# MAX32600 register map
File version: 1.0
Registers are 32-bit, read-write, reset 0x0 unless marked. A register's access mark holds for its fields unless they carry their own. Offsets are from the block's base; [hi:lo] are bit positions; {n}, {i} and the like mark numbered series.

## AFE — Analog Front End Controls
Base 0x4005401C
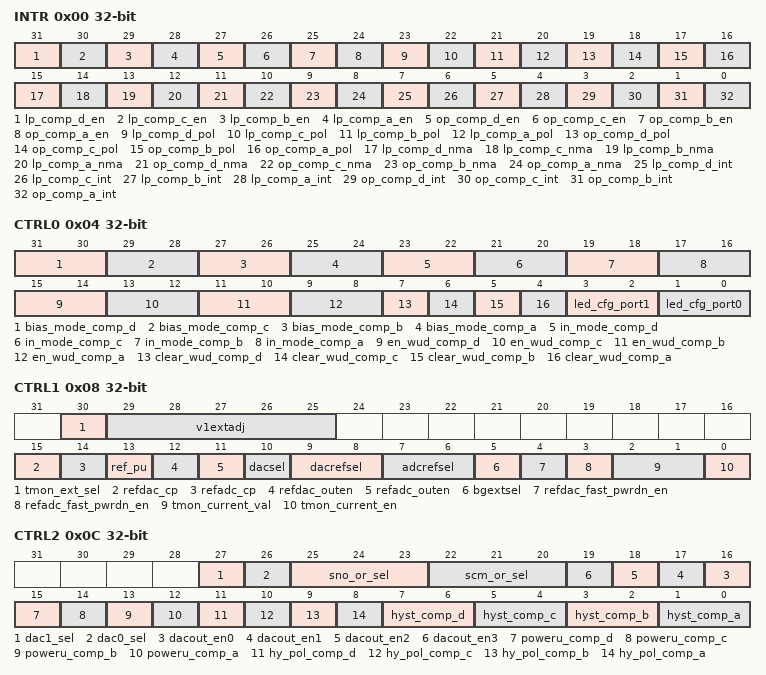
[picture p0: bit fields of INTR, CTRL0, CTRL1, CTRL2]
0x00 INTR — Analog Front End Interrupt Flags and Enable/Disable
  [31] lp_comp_d_en — Low-Power Comparator D Interrupt Enable/Disable
  [30] lp_comp_c_en — Low-Power Comparator C Interrupt Enable/Disable
  [29] lp_comp_b_en — Low-Power Comparator B Interrupt Enable/Disable
  [28] lp_comp_a_en — Low-Power Comparator A Interrupt Enable/Disable
  [27] op_comp_d_en — Op Amp Comparator D Interrupt Enable/Disable
  [26] op_comp_c_en — Op Amp Comparator C Interrupt Enable/Disable
  [25] op_comp_b_en — Op Amp Comparator B Interrupt Enable/Disable
  [24] op_comp_a_en — Op Amp Comparator A Interrupt Enable/Disable
  [23] lp_comp_d_pol — Low-Power Comparator D Polarity Select
  [22] lp_comp_c_pol — Low-Power Comparator C Polarity Select
  [21] lp_comp_b_pol — Low-Power Comparator B Polarity Select
  [20] lp_comp_a_pol — Low-Power Comparator A Polarity Select
  [19] op_comp_d_pol — Op Amp Comparator D Polarity Select
  [18] op_comp_c_pol — Op Amp Comparator C Polarity Select
  [17] op_comp_b_pol — Op Amp Comparator B Polarity Select
  [16] op_comp_a_pol — Op Amp Comparator A Polarity Select
  [15] lp_comp_d_nma write-1-clears — Low-Power Comparator D Non-Maskable Event Flag
  [14] lp_comp_c_nma write-1-clears — Low-Power Comparator C Non-Maskable Event Flag
  [13] lp_comp_b_nma write-1-clears — Low-Power Comparator B Non-Maskable Event Flag
  [12] lp_comp_a_nma write-1-clears — Low-Power Comparator A Non-Maskable Event Flag
  [11] op_comp_d_nma write-1-clears — Op Amp Comparator D Non-Maskable Event Flag
  [10] op_comp_c_nma write-1-clears — Op Amp Comparator C Non-Maskable Event Flag
  [9] op_comp_b_nma write-1-clears — Op Amp Comparator B Non-Maskable Event Flag
  [8] op_comp_a_nma write-1-clears — Op Amp Comparator A Non-Maskable Event Flag
  [7] lp_comp_d_int write-1-clears — Low-Power Comparator D Event Interrupt Flag
  [6] lp_comp_c_int write-1-clears — Low-Power Comparator C Event Interrupt Flag
  [5] lp_comp_b_int write-1-clears — Low-Power Comparator B Event Interrupt Flag
  [4] lp_comp_a_int write-1-clears — Low-Power Comparator A Event Interrupt Flag
  [3] op_comp_d_int write-1-clears — Op Amp D Comparator Event Interrupt Flag
  [2] op_comp_c_int write-1-clears — Op Amp C Comparator Event Interrupt Flag
  [1] op_comp_b_int write-1-clears — Op Amp B Comparator Event Interrupt Flag
  [0] op_comp_a_int write-1-clears — Op Amp A Comparator Event Interrupt Flag
0x04 CTRL0 — Analog Front End Control 0
  [31:30] bias_mode_comp_d — Low-Power Comparator D Bias Mode
  [29:28] bias_mode_comp_c — Low-Power Comparator C Bias Mode
  [27:26] bias_mode_comp_b — Low-Power Comparator B Bias Mode
  [25:24] bias_mode_comp_a — Low-Power Comparator A Bias Mode
  [23:22] in_mode_comp_d — Low-Power Comparator D Input Mode
  [21:20] in_mode_comp_c — Low-Power Comparator C Input Mode
  [19:18] in_mode_comp_b — Low-Power Comparator A Input Mode
  [17:16] in_mode_comp_a — Low-Power Comparator A Input Mode
  [15:14] en_wud_comp_d — Set Wakeup Detect for Low-Power Comparator D
  [13:12] en_wud_comp_c — Set Wakeup Detect for Low-Power Comparator C
  [11:10] en_wud_comp_b — Set Wakeup Detect for Low-Power Comparator B
  [9:8] en_wud_comp_a — Set Wakeup Detect for Low-Power Comparator A
  [7] clear_wud_comp_d — Clear Wakeup Detect for Low-Power Comparator D
  [6] clear_wud_comp_c — Clear Wakeup Detect for Low-Power Comparator C
  [5] clear_wud_comp_b — Clear Wakeup Detect for Low-Power Comparator B
  [4] clear_wud_comp_a — Clear Wakeup Detect for Low-Power Comparator A
  [3:2] led_cfg_port1 — LED Port 1 Drive Configuration
  [1:0] led_cfg_port0 — LED Port 0 Drive Configuration
0x08 CTRL1 — Analog Front End Control 1
  [30] tmon_ext_sel — Temperature Sense Current Source Routing Select
  [29:25] v1extadj
  [15] refdac_cp — DAC Reference Compensation Enable
  [14] refadc_cp — ADC Reference Compensation Enable
  [13] ref_pu — Reference Block Powerup
  [12] refdac_outen — DAC Reference Powerup
  [11] refadc_outen — Internal ADC Reference Output Enable
  [10] dacsel — DAC Reference Select
  [9:8] dacrefsel — DAC Reference Voltage Select
  [7:6] adcrefsel — ADC Reference Voltage Select
  [5] bgextsel — ADC/DAC Reference Select
  [4] refdac_fast_pwrdn_en — DAC Reference Fast Powerdown Enable
  [3] refadc_fast_pwrdn_en — ADC Reference Fast Powerdown Enable
  [2:1] tmon_current_val — Temperature Sense Current Source Value
  [0] tmon_current_en — Temperature Sense Current Source Enable
0x0C CTRL2 — Analog Front End Control 2
  [27] dac1_sel — Internal input stage select for dac1
  [26] dac0_sel — Internal input stage select for dac0
  [25:23] sno_or_sel — Selects source for SNO_or signal
  [22:20] scm_or_sel — Selects source for SCM_or signal
  [n+16] dacout_en{n} (n=0..3) — Connects DAC_orx output selected by DAC_selx to SNOx
  [15] poweru_comp_d — Low-Power Comparator D Powerup/Enable
  [14] poweru_comp_c — Low-Power Comparator C Powerup/Enable
  [13] poweru_comp_b — Low-Power Comparator B Powerup/Enable
  [12] poweru_comp_a — Low-Power Comparator A Powerup/Enable
  [11] hy_pol_comp_d — Low-Power Comparator D Hysteresis Polarity Select
  [10] hy_pol_comp_c — Low-Power Comparator C Hysteresis Polarity Select
  [9] hy_pol_comp_b — Low-Power Comparator B Hysteresis Polarity Select
  [8] hy_pol_comp_a — Low-Power Comparator A Hysteresis Polarity Select
  [7:6] hyst_comp_d — Low-Power Comparator D Hysteresis Magnitude Select
  [5:4] hyst_comp_c — Low-Power Comparator C Hysteresis Magnitude Select
  [3:2] hyst_comp_b — Low-Power Comparator B Hysteresis Magnitude Select
  [1:0] hyst_comp_a — Low-Power Comparator A Hysteresis Magnitude Select
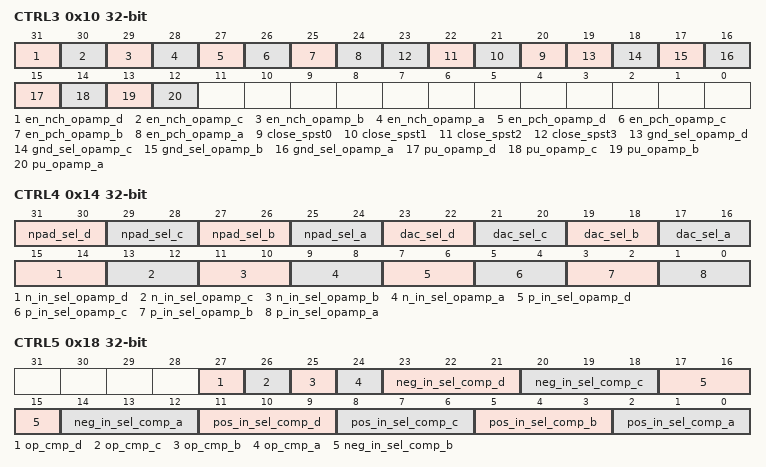
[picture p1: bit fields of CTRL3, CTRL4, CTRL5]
0x10 CTRL3 — Analog Front End Control 3
  [31] en_nch_opamp_d — Op Amp D N-Channel Input Stage Enable
  [30] en_nch_opamp_c — Op Amp C N-Channel Input Stage Enable
  [29] en_nch_opamp_b — Op Amp B N-Channel Input Stage Enable
  [28] en_nch_opamp_a — Op Amp A N-Channel Input Stage Enable
  [27] en_pch_opamp_d — Op Amp D P-Channel Input Stage Enable
  [26] en_pch_opamp_c — Op Amp C P-Channel Input Stage Enable
  [25] en_pch_opamp_b — Op Amp B P-Channel Input Stage Enable
  [24] en_pch_opamp_a — Op Amp A P-Channel Input Stage Enable
  [n+20] close_spst{n} (n=0..3) — Switch Close for SPST{n}
  [19] gnd_sel_opamp_d — Op Amp D Positive Input Ground Select
  [18] gnd_sel_opamp_c — Op Amp C Positive Input Ground Select
  [17] gnd_sel_opamp_b — Op Amp B Positive Input Ground Select
  [16] gnd_sel_opamp_a — Op Amp A Positive Input Ground Select
  [15] pu_opamp_d — Op Amp D Power Up
  [14] pu_opamp_c — Op Amp C Power Up
  [13] pu_opamp_b — Op Amp B Power Up
  [12] pu_opamp_a — Op Amp A Power Up
0x14 CTRL4 — Analog Front End Control 4
  [31:30] npad_sel_d — Pad Internal Connect to IND-
  [29:28] npad_sel_c — Pad Internal Connect to INC-
  [27:26] npad_sel_b — Pad Internal Connect to INB-
  [25:24] npad_sel_a — Pad Internal Connect to INA-
  [23:22] dac_sel_d — DAC Output Mux Select to dac_or3 Stage
  [21:20] dac_sel_c — DAC Output Mux Select to dac_or2 Stage
  [19:18] dac_sel_b — DAC Output Mux Select to dac_or1 Stage
  [17:16] dac_sel_a — DAC Output Mux Select to dac_or0 Stage
  [15:14] n_in_sel_opamp_d — Op Amp D Negative Input Select
  [13:12] n_in_sel_opamp_c — Op Amp C Negative Input Select
  [11:10] n_in_sel_opamp_b — Op Amp B Negative Input Select
  [9:8] n_in_sel_opamp_a — Op Amp A Negative Input Select
  [7:6] p_in_sel_opamp_d — Op Amp D Positive Input Select
  [5:4] p_in_sel_opamp_c — Op Amp C Positive Input Select
  [3:2] p_in_sel_opamp_b — Op Amp B Positive Input Select
  [1:0] p_in_sel_opamp_a — Op Amp A Positive Input Select
0x18 CTRL5 — Analog Front End Control 5
  [27] op_cmp_d — Mode Select for Op Amp D
  [26] op_cmp_c — Mode Select for Op Amp C
  [25] op_cmp_b — Mode Select for Op Amp B
  [24] op_cmp_a — Mode Select for Op Amp A
  [23:21] neg_in_sel_comp_d — Low-Power Comparator D Negative Input Select
  [20:18] neg_in_sel_comp_c — Low-Power Comparator C Negative Input Select
  [17:15] neg_in_sel_comp_b — Low-Power Comparator B Negative Input Select
  [14:12] neg_in_sel_comp_a — Low-Power Comparator A Negative Input Select
  [11:9] pos_in_sel_comp_d — Low-Power Comparator D Positive Input Select
  [8:6] pos_in_sel_comp_c — Low-Power Comparator C Positive Input Select
  [5:3] pos_in_sel_comp_b — Low-Power Comparator B Positive Input Select
  [2:0] pos_in_sel_comp_a — Low-Power Comparator A Positive Input Select
